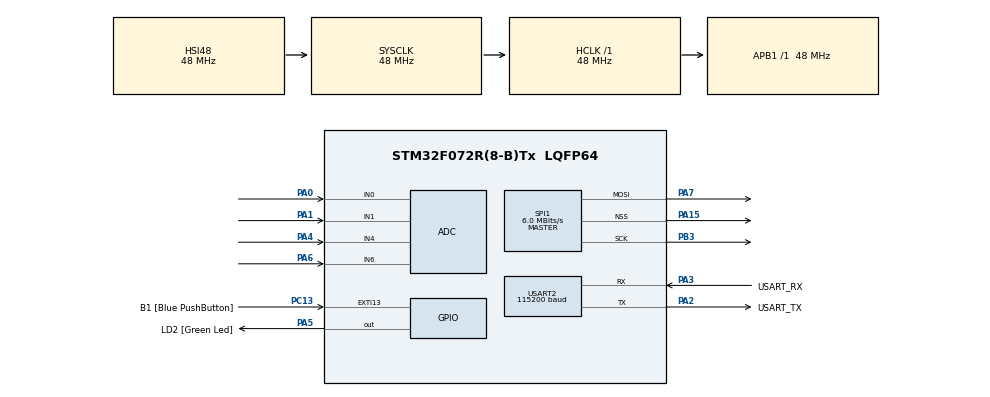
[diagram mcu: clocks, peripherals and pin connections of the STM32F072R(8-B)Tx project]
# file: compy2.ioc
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Mcu.Family=STM32F0
Mcu.Name=STM32F072R(8-B)Tx
Mcu.Package=LQFP64
PA0.Mode=IN0
PA0.Signal=ADC_IN0
PA1.Mode=IN1
PA1.Signal=ADC_IN1
PA13.GPIO_Label=TMS
PA13.Mode=Serial_Wire
PA13.Signal=SYS_SWDIO
PA14.GPIO_Label=TCK
PA14.Mode=Serial_Wire
PA14.Signal=SYS_SWCLK
PA15.Mode=NSS_Signal_Hard_Output
PA15.Signal=SPI1_NSS
PA2.GPIO_Label=USART_TX
PA2.GPIO_Mode=GPIO_MODE_AF_PP
PA2.GPIO_PuPd=GPIO_NOPULL
PA2.GPIO_Speed=GPIO_SPEED_FREQ_LOW
PA2.Mode=Asynchronous
PA2.Signal=USART2_TX
PA3.GPIO_Label=USART_RX
PA3.GPIO_Mode=GPIO_MODE_AF_PP
PA3.GPIO_PuPd=GPIO_NOPULL
PA3.GPIO_Speed=GPIO_SPEED_FREQ_LOW
PA3.Mode=Asynchronous
PA3.Signal=USART2_RX
PA4.Mode=IN4
PA4.Signal=ADC_IN4
PA5.GPIO_Label=LD2 [Green Led]
PA5.GPIO_Mode=GPIO_MODE_OUTPUT_PP
PA5.GPIO_PuPd=GPIO_NOPULL
PA5.GPIO_Speed=GPIO_SPEED_FREQ_LOW
PA5.Signal=GPIO_Output
PA6.Mode=IN6
PA6.Signal=ADC_IN6
PA7.Mode=TX_Only_Simplex_Unidirect_Master
PA7.Signal=SPI1_MOSI
PB3.Mode=TX_Only_Simplex_Unidirect_Master
PB3.Signal=SPI1_SCK
PC13.GPIO_Label=B1 [Blue PushButton]
PC13.GPIO_ModeDefaultEXTI=GPIO_MODE_IT_FALLING
PC13.Signal=GPXTI13
PC14-OSC32_IN.Mode=LSE-External-Oscillator
PC14-OSC32_IN.Signal=RCC_OSC32_IN
PC15-OSC32_OUT.Mode=LSE-External-Oscillator
PC15-OSC32_OUT.Signal=RCC_OSC32_OUT
PF0-OSC_IN.Mode=HSE-External-Clock-Source
PF0-OSC_IN.Signal=RCC_OSC_IN
PF1-OSC_OUT.Signal=RCC_OSC_OUT
ProjectManager.HeapSize=0x200
ProjectManager.StackSize=0x400
ProjectManager.TargetToolchain=STM32CubeIDE
RCC.AHBFreq_Value=48000000
RCC.APB1Freq_Value=48000000
RCC.APB1TimFreq_Value=48000000
RCC.FLatency-AdvancedSettings=FLASH_LATENCY_1
RCC.HCLKFreq_Value=48000000
RCC.PLLDivider=RCC_PREDIV_DIV2
RCC.PLLMUL=RCC_PLL_MUL12
RCC.PREFETCH_ENABLE-AdvancedSettings=1
RCC.SYSCLKFreq_VALUE=48000000
RCC.SYSCLKSource=RCC_SYSCLKSOURCE_HSI48
SPI1.BaudRatePrescaler=SPI_BAUDRATEPRESCALER_8
SPI1.CalculateBaudRate=6.0 MBits/s
SPI1.DataSize=SPI_DATASIZE_8BIT
SPI1.Direction=SPI_DIRECTION_2LINES
SPI1.Mode=SPI_MODE_MASTER
SPI1.VirtualNSS=VM_NSSHARD
SPI1.VirtualType=VM_MASTER
USART2.BaudRate=115200
USART2.VirtualMode=VM_ASYNC
USART2.VirtualMode-Asynchronous=VM_ASYNC
board=NUCLEO-F072RB

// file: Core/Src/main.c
/* USER CODE BEGIN Header */
/**
  ******************************************************************************
  * @file           : main.c
  * @brief          : Main program body
  ******************************************************************************
  * @attention
  *
  * Copyright (c) 2023 STMicroelectronics.
  * All rights reserved.
  *
  * This software is licensed under terms that can be found in the LICENSE file
  * in the root directory of this software component.
  * If no LICENSE file comes with this software, it is provided AS-IS.
  *
  ******************************************************************************
  */
/* USER CODE END Header */
#include "main.h"

ADC_HandleTypeDef hadc;

SPI_HandleTypeDef hspi1;

UART_HandleTypeDef huart2;

void SystemClock_Config(void);
static void MX_GPIO_Init(void);
static void MX_USART2_UART_Init(void);
static void MX_ADC_Init(void);
static void MX_SPI1_Init(void);
/* USER CODE BEGIN PFP */
#define PUTCHAR_PROTOTYPE int __io_putchar(int ch)
/* USER CODE END PFP */

int main(void)
{

  /* MCU Configuration--------------------------------------------------------*/

  /* Reset of all peripherals, Initializes the Flash interface and the Systick. */
  HAL_Init();

  /* Configure the system clock */
  SystemClock_Config();

  /* Initialize all configured peripherals */
  MX_GPIO_Init();
  MX_USART2_UART_Init();
  MX_ADC_Init();
  MX_SPI1_Init();
  /* USER CODE BEGIN 2 */

  printf("Hi1\n");
  printf("Hi2\n");
  printf("Hi3\n");

  /* USER CODE END 2 */

  /* Infinite loop */
  while (1)
  {

  }
}

void SystemClock_Config(void)
{
  RCC_OscInitTypeDef RCC_OscInitStruct = {0};
  RCC_ClkInitTypeDef RCC_ClkInitStruct = {0};
  RCC_PeriphCLKInitTypeDef PeriphClkInit = {0};

  /** Initializes the RCC Oscillators according to the specified parameters
  * in the RCC_OscInitTypeDef structure.
  */
  RCC_OscInitStruct.OscillatorType = RCC_OSCILLATORTYPE_HSI14|RCC_OSCILLATORTYPE_HSI48;
  RCC_OscInitStruct.HSI48State = RCC_HSI48_ON;
  RCC_OscInitStruct.HSI14State = RCC_HSI14_ON;
  RCC_OscInitStruct.HSI14CalibrationValue = 16;
  RCC_OscInitStruct.PLL.PLLState = RCC_PLL_NONE;
  if (HAL_RCC_OscConfig(&RCC_OscInitStruct) != HAL_OK)
  {
    Error_Handler();
  }

  /** Initializes the CPU, AHB and APB buses clocks
  */
  RCC_ClkInitStruct.ClockType = RCC_CLOCKTYPE_HCLK|RCC_CLOCKTYPE_SYSCLK
                              |RCC_CLOCKTYPE_PCLK1;
  RCC_ClkInitStruct.SYSCLKSource = RCC_SYSCLKSOURCE_HSI48;
  RCC_ClkInitStruct.AHBCLKDivider = RCC_SYSCLK_DIV1;
  RCC_ClkInitStruct.APB1CLKDivider = RCC_HCLK_DIV1;

  if (HAL_RCC_ClockConfig(&RCC_ClkInitStruct, FLASH_LATENCY_1) != HAL_OK)
  {
    Error_Handler();
  }
  PeriphClkInit.PeriphClockSelection = RCC_PERIPHCLK_USART2;
  PeriphClkInit.Usart2ClockSelection = RCC_USART2CLKSOURCE_PCLK1;
  if (HAL_RCCEx_PeriphCLKConfig(&PeriphClkInit) != HAL_OK)
  {
    Error_Handler();
  }
}

static void MX_ADC_Init(void)
{

  ADC_ChannelConfTypeDef sConfig = {0};

  /** Configure the global features of the ADC (Clock, Resolution, Data Alignment and number of conversion)
  */
  hadc.Instance = ADC1;
  hadc.Init.ClockPrescaler = ADC_CLOCK_ASYNC_DIV1;
  hadc.Init.Resolution = ADC_RESOLUTION_12B;
  hadc.Init.DataAlign = ADC_DATAALIGN_RIGHT;
  hadc.Init.ScanConvMode = ADC_SCAN_DIRECTION_FORWARD;
  hadc.Init.EOCSelection = ADC_EOC_SINGLE_CONV;
  hadc.Init.LowPowerAutoWait = DISABLE;
  hadc.Init.LowPowerAutoPowerOff = DISABLE;
  hadc.Init.ContinuousConvMode = DISABLE;
  hadc.Init.DiscontinuousConvMode = DISABLE;
  hadc.Init.ExternalTrigConv = ADC_SOFTWARE_START;
  hadc.Init.ExternalTrigConvEdge = ADC_EXTERNALTRIGCONVEDGE_NONE;
  hadc.Init.DMAContinuousRequests = DISABLE;
  hadc.Init.Overrun = ADC_OVR_DATA_PRESERVED;
  if (HAL_ADC_Init(&hadc) != HAL_OK)
  {
    Error_Handler();
  }

  /** Configure for the selected ADC regular channel to be converted.
  */
  sConfig.Channel = ADC_CHANNEL_0;
  sConfig.Rank = ADC_RANK_CHANNEL_NUMBER;
  sConfig.SamplingTime = ADC_SAMPLETIME_1CYCLE_5;
  if (HAL_ADC_ConfigChannel(&hadc, &sConfig) != HAL_OK)
  {
    Error_Handler();
  }

  /** Configure for the selected ADC regular channel to be converted.
  */
  sConfig.Channel = ADC_CHANNEL_1;
  if (HAL_ADC_ConfigChannel(&hadc, &sConfig) != HAL_OK)
  {
    Error_Handler();
  }

  /** Configure for the selected ADC regular channel to be converted.
  */
  sConfig.Channel = ADC_CHANNEL_4;
  if (HAL_ADC_ConfigChannel(&hadc, &sConfig) != HAL_OK)
  {
    Error_Handler();
  }

  /** Configure for the selected ADC regular channel to be converted.
  */
  sConfig.Channel = ADC_CHANNEL_6;
  if (HAL_ADC_ConfigChannel(&hadc, &sConfig) != HAL_OK)
  {
    Error_Handler();
  }

}

static void MX_SPI1_Init(void)
{

  /* SPI1 parameter configuration*/
  hspi1.Instance = SPI1;
  hspi1.Init.Mode = SPI_MODE_MASTER;
  hspi1.Init.Direction = SPI_DIRECTION_2LINES;
  hspi1.Init.DataSize = SPI_DATASIZE_8BIT;
  hspi1.Init.CLKPolarity = SPI_POLARITY_LOW;
  hspi1.Init.CLKPhase = SPI_PHASE_1EDGE;
  hspi1.Init.NSS = SPI_NSS_HARD_OUTPUT;
  hspi1.Init.BaudRatePrescaler = SPI_BAUDRATEPRESCALER_8;
  hspi1.Init.FirstBit = SPI_FIRSTBIT_MSB;
  hspi1.Init.TIMode = SPI_TIMODE_DISABLE;
  hspi1.Init.CRCCalculation = SPI_CRCCALCULATION_DISABLE;
  hspi1.Init.CRCPolynomial = 7;
  hspi1.Init.CRCLength = SPI_CRC_LENGTH_DATASIZE;
  hspi1.Init.NSSPMode = SPI_NSS_PULSE_ENABLE;
  if (HAL_SPI_Init(&hspi1) != HAL_OK)
  {
    Error_Handler();
  }

}

static void MX_USART2_UART_Init(void)
{

  huart2.Instance = USART2;
  huart2.Init.BaudRate = 115200;
  huart2.Init.WordLength = UART_WORDLENGTH_8B;
  huart2.Init.StopBits = UART_STOPBITS_1;
  huart2.Init.Parity = UART_PARITY_NONE;
  huart2.Init.Mode = UART_MODE_TX_RX;
  huart2.Init.HwFlowCtl = UART_HWCONTROL_NONE;
  huart2.Init.OverSampling = UART_OVERSAMPLING_16;
  huart2.Init.OneBitSampling = UART_ONE_BIT_SAMPLE_DISABLE;
  huart2.AdvancedInit.AdvFeatureInit = UART_ADVFEATURE_NO_INIT;
  if (HAL_UART_Init(&huart2) != HAL_OK)
  {
    Error_Handler();
  }

}

static void MX_GPIO_Init(void)
{
  GPIO_InitTypeDef GPIO_InitStruct = {0};

  /* GPIO Ports Clock Enable */
  __HAL_RCC_GPIOC_CLK_ENABLE();
  __HAL_RCC_GPIOF_CLK_ENABLE();
  __HAL_RCC_GPIOA_CLK_ENABLE();
  __HAL_RCC_GPIOB_CLK_ENABLE();

  /*Configure GPIO pin Output Level */
  HAL_GPIO_WritePin(LD2_GPIO_Port, LD2_Pin, GPIO_PIN_RESET);

  /*Configure GPIO pin : B1_Pin */
  GPIO_InitStruct.Pin = B1_Pin;
  GPIO_InitStruct.Mode = GPIO_MODE_IT_FALLING;
  GPIO_InitStruct.Pull = GPIO_NOPULL;
  HAL_GPIO_Init(B1_GPIO_Port, &GPIO_InitStruct);

  /*Configure GPIO pin : LD2_Pin */
  GPIO_InitStruct.Pin = LD2_Pin;
  GPIO_InitStruct.Mode = GPIO_MODE_OUTPUT_PP;
  GPIO_InitStruct.Pull = GPIO_NOPULL;
  GPIO_InitStruct.Speed = GPIO_SPEED_FREQ_LOW;
  HAL_GPIO_Init(LD2_GPIO_Port, &GPIO_InitStruct);

}

/* USER CODE BEGIN 4 */
/**
  * @brief  Retargets the C library printf function to the USART.
  * @param  None
  * @retval None
  */
PUTCHAR_PROTOTYPE
{
  /* Place your implementation of fputc here */
  /* e.g. write a character to the USART1 and Loop until the end of transmission */
  HAL_UART_Transmit(&huart2, (uint8_t *)&ch, 1, 0xFFFF);
  if (ch=='\n')
  {
	  HAL_UART_Transmit(&huart2, "\r", 1, 0xFFFF);
  }

  return ch;
}
/* USER CODE END 4 */

void Error_Handler(void)
{
  __disable_irq();
  while (1)
  {
  }
}
